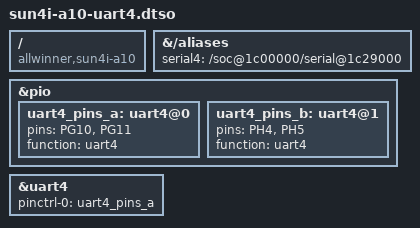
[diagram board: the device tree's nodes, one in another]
/dts-v1/;
/plugin/;

/ {
	compatible = "allwinner,sun4i-a10";

	fragment@0 {
		target-path = "/aliases";
		__overlay__ {
			serial4 = "/soc@1c00000/serial@1c29000";
		};
	};

	fragment@1 {
		target = <&pio>;
		__overlay__ {
			uart4_pins_a: uart4@0 {
				pins = "PG10", "PG11";
				function = "uart4";
			};

			uart4_pins_b: uart4@1 {
				pins = "PH4", "PH5";
				function = "uart4";
			};
		};
	};

	fragment@2 {
		target = <&uart4>;
		 __overlay__ {
			pinctrl-names = "default";
			pinctrl-0 = <&uart4_pins_a>;
			status = "okay";
		};
	};
};
